AUTOSAR XML (schema 00049)
package /Application/DltConfig
  dlt log channel to process mapping DltLogChannelToProcessMapping_SOA_Debugger_TO_SOA_Debugger: dlt-log-channel=SOA_Debugger, process=SOA_Debugger
package /Application/Executable
  executable SOA_Debugger: category=APPLICATION_LEVEL, logging-behavior=USES-LOGGING, reporting-behavior=REPORTS-EXECUTION-STATE, version=1.0.0
    root sw component prototype AA: application-type=SOA_Debugger
package /Application/Manifest
  9 x service instance to port prototype mapping, all with process=SOA_Debugger:
    SOA_Debugger_AA_RPort_SOADBG_Dms: port-prototype=AA.RPort_SOADBG_Dms, service-instance=Consumer_SoaDms
    SOA_Debugger_AA_RPort_SOADBG_DriverSeat: port-prototype=AA.RPort_SOADBG_DriverSeat, service-instance=Consumer_SoaDriverSeat
    SOA_Debugger_AA_RPort_SOADBG_Hvac: port-prototype=AA.RPort_SOADBG_Hvac, service-instance=Consumer_SoaHvac
    SOA_Debugger_AA_RPort_SOADBG_MoodLamp: port-prototype=AA.RPort_SOADBG_MoodLamp, service-instance=Consumer_SoaMlm
    SOA_Debugger_AA_RPort_SOADBG_Power: port-prototype=AA.RPort_SOADBG_Power, service-instance=Consumer_SoaPower
    SOA_Debugger_AA_RPort_SOADBG_ROA: port-prototype=AA.RPort_SOADBG_ROA, service-instance=Consumer_SoaRoa
    SOA_Debugger_AA_RPort_SOADBG_RearCurtain: port-prototype=AA.RPort_SOADBG_RearCurtain, service-instance=Consumer_SoaRcurtain
    SOA_Debugger_AA_RPort_SOADBG_SmartFilm: port-prototype=AA.RPort_SOADBG_SmartFilm, service-instance=Consumer_SoaSmartFilm
    SOA_Debugger_AA_RPort_SOADBG_Wiper: port-prototype=AA.RPort_SOADBG_Wiper, service-instance=Consumer_SoaWiper
package /Application/Process
  process SOA_Debugger: executable=SOA_Debugger, state-dependent-startup-config{function-group-state=SC.On, resource-group=DefaultResourceGroup, startup-config=SOA}
    process state machine SOA_Debugger: type=ProcessState
package /Application/SwComponent
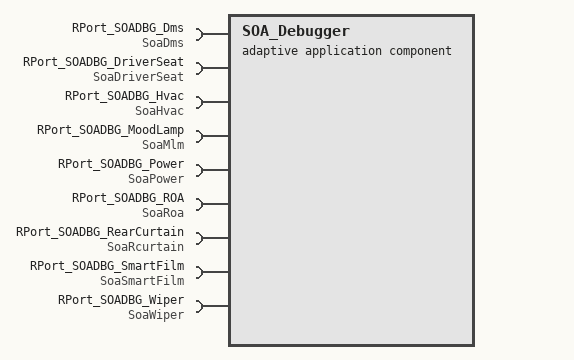
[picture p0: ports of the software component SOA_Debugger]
  adaptive application sw component type SOA_Debugger
    9 x require port:
      RPort_SOADBG_Dms: required-interface=SoaDms
      RPort_SOADBG_DriverSeat: required-interface=SoaDriverSeat
      RPort_SOADBG_Hvac: required-interface=SoaHvac
      RPort_SOADBG_MoodLamp: required-interface=SoaMlm
      RPort_SOADBG_Power: required-interface=SoaPower
      RPort_SOADBG_ROA: required-interface=SoaRoa
      RPort_SOADBG_RearCurtain: required-interface=SoaRcurtain
      RPort_SOADBG_SmartFilm: required-interface=SoaSmartFilm
      RPort_SOADBG_Wiper: required-interface=SoaWiper
